# ATmega1284RFR2 device description
Architecture: AVR8; Family: megaAVR
Registers are 8-bit, access not given, no defined reset value unless marked. A register's access mark holds for its fields unless they carry their own. Offsets are from the block's base; [hi:lo] are bit positions; {n}, {i} and the like mark numbered series.

## LOCKBIT — Lockbits
Instances: LOCKBIT 0 in lockbits
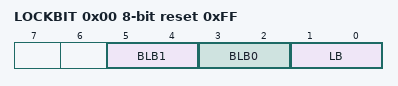
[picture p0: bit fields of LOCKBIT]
0x00 LOCKBIT reset 0xFF
  [5:4] BLB1 — Boot Loader Protection Mode
    0=LPM_SPM_DISABLE (LPM and SPM prohibited in Boot Section); 1=LPM_DISABLE (LPM prohibited in Boot Section); 2=SPM_DISABLE (SPM prohibited in Boot Section); 3=NO_LOCK (No lock on SPM and LPM in Boot Section)
  [3:2] BLB0 — Boot Loader Protection Mode
    0=LPM_SPM_DISABLE (LPM and SPM prohibited in Application Section); 1=LPM_DISABLE (LPM prohibited in Application Section); 2=SPM_DISABLE (SPM prohibited in Application Section); 3=NO_LOCK (No lock on SPM and LPM in Application Section)
  [1:0] LB — Memory Lock
    0=PROG_VER_DISABLED (Further programming and verification disabled); 2=PROG_DISABLED (Further programming disabled); 3=NO_LOCK (No memory lock features enabled)

## AC — Analog Comparator
Instances: AC 0x00
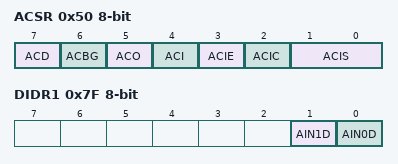
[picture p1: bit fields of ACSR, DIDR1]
0x50 ACSR — Analog Comparator Control And Status Register
  [7] ACD — Analog Comparator Disable
  [6] ACBG — Analog Comparator Bandgap Select
  [5] ACO — Analog Compare Output
  [4] ACI — Analog Comparator Interrupt Flag
  [3] ACIE — Analog Comparator Interrupt Enable
  [2] ACIC — Analog Comparator Input Capture Enable
  [1:0] ACIS — Analog Comparator Interrupt Mode Select
    0=Interrupt on Toggle; 2=Interrupt on Falling Edge; 3=Interrupt on Rising Edge
0x7B ADCSRB — ADC Control and Status Register B
  [6] ACME — Analog Comparator Multiplexer Enable
0x7F DIDR1 — Digital Input Disable Register 1
  [1] AIN1D — AIN1 Digital Input Disable
  [0] AIN0D — AIN0 Digital Input Disable

## USART0 — USART
Instances: USART0 0x00
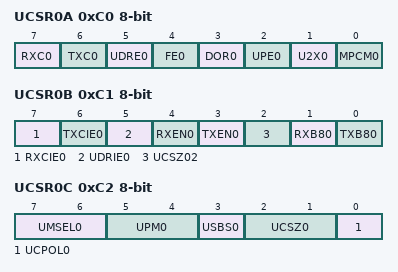
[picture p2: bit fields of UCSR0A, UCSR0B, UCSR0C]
0xC0 UCSR0A — USART0 Control and Status Register A
  [7] RXC0 — USART Receive Complete
  [6] TXC0 — USART Transmit Complete
  [5] UDRE0 — USART Data Register Empty
  [4] FE0 — Frame Error
  [3] DOR0 — Data OverRun
  [2] UPE0 — USART Parity Error
  [1] U2X0 — Double the USART Transmission Speed
  [0] MPCM0 — Multi-processor Communication Mode
0xC1 UCSR0B — USART0 Control and Status Register B
  [7] RXCIE0 — RX Complete Interrupt Enable
  [6] TXCIE0 — TX Complete Interrupt Enable
  [5] UDRIE0 — USART Data Register Empty Interrupt Enable
  [4] RXEN0 — Receiver Enable
  [3] TXEN0 — Transmitter Enable
  [2] UCSZ02 — Character Size
  [1] RXB80 — Receive Data Bit 8
  [0] TXB80 — Transmit Data Bit 8
0xC2 UCSR0C — USART0 Control and Status Register C
  [7:6] UMSEL0 — USART Mode Select
    0=Asynchronous USART; 1=Synchronous USART; 3=Master SPI (MSPIM)
  [5:4] UPM0 — Parity Mode
    0=Disabled; 2=Enabled, Even Parity; 3=Enabled, Odd Parity
  [3] USBS0 — Stop Bit Select
    0=1-bit; 1=2-bit
  [2:1] UCSZ0 — Character Size
    {v}={v+5}-bit (v=0..3); 7=9-bit
  [0] UCPOL0 — Clock Polarity
    0=Rising XCKn Edge (Transmitted Data Changed), Falling XCKn Edge (Received Data Sampled); 1=Falling XCKn Edge (Transmitted Data Changed), Rising XCKn Edge (Received Data Sampled)
0xC4 UBRR0 16-bit — USART0 Baud Rate Register Bytes
0xC6 UDR0 — USART0 I/O Data Register

## USART1 — USART
Instances: USART1 0x00
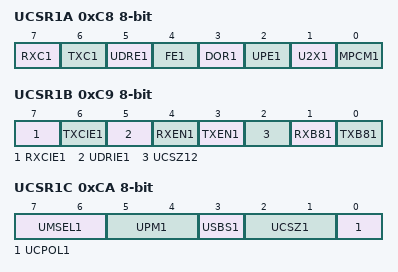
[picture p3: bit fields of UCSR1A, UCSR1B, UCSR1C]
0xC8 UCSR1A — USART1 Control and Status Register A
  [7] RXC1 — USART Receive Complete
  [6] TXC1 — USART Transmit Complete
  [5] UDRE1 — USART Data Register Empty
  [4] FE1 — Frame Error
  [3] DOR1 — Data OverRun
  [2] UPE1 — USART Parity Error
  [1] U2X1 — Double the USART Transmission Speed
  [0] MPCM1 — Multi-processor Communication Mode
0xC9 UCSR1B — USART1 Control and Status Register B
  [7] RXCIE1 — RX Complete Interrupt Enable
  [6] TXCIE1 — TX Complete Interrupt Enable
  [5] UDRIE1 — USART Data Register Empty Interrupt Enable
  [4] RXEN1 — Receiver Enable
  [3] TXEN1 — Transmitter Enable
  [2] UCSZ12 — Character Size
  [1] RXB81 — Receive Data Bit 8
  [0] TXB81 — Transmit Data Bit 8
0xCA UCSR1C — USART1 Control and Status Register C
  [7:6] UMSEL1 — USART Mode Select
    0=Asynchronous USART; 1=Synchronous USART; 3=Master SPI (MSPIM)
  [5:4] UPM1 — Parity Mode
    0=Disabled; 2=Enabled, Even Parity; 3=Enabled, Odd Parity
  [3] USBS1 — Stop Bit Select
    0=1-bit; 1=2-bit
  [2:1] UCSZ1 — Character Size
    {v}={v+5}-bit (v=0..3); 7=9-bit
  [0] UCPOL1 — Clock Polarity
    0=Rising XCKn Edge (Transmitted Data Changed), Falling XCKn Edge (Received Data Sampled); 1=Falling XCKn Edge (Transmitted Data Changed), Rising XCKn Edge (Received Data Sampled)
0xCC UBRR1 16-bit — USART1 Baud Rate Register Bytes
0xCE UDR1 — USART1 I/O Data Register
